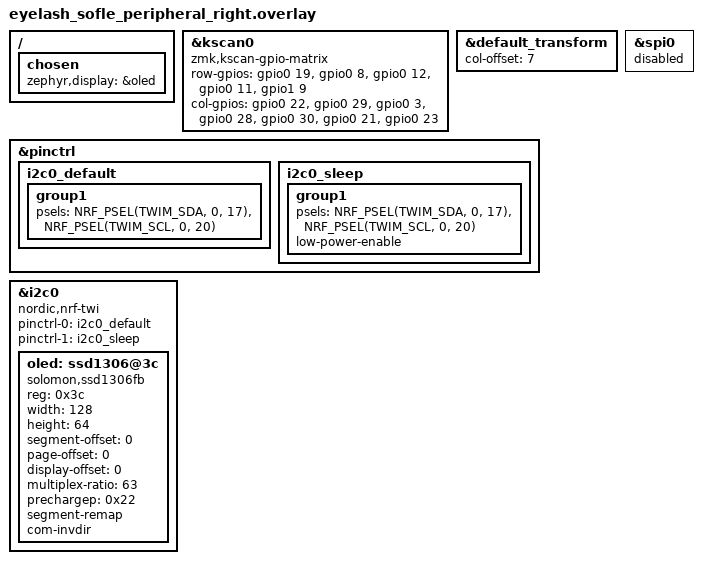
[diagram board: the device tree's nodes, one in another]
/*
*
* Copyright (c) 2021 Darryl deHaan
* SPDX-License-Identifier: MIT
*
*/
#include "eyelash_sofle.dtsi"

&kscan0 {
    compatible = "zmk,kscan-gpio-matrix";
    row-gpios
        = <&gpio0 19 (GPIO_ACTIVE_HIGH | GPIO_PULL_DOWN)>
        , <&gpio0 8 (GPIO_ACTIVE_HIGH | GPIO_PULL_DOWN)>
        , <&gpio0 12 (GPIO_ACTIVE_HIGH | GPIO_PULL_DOWN)>
        , <&gpio0 11 (GPIO_ACTIVE_HIGH | GPIO_PULL_DOWN)>
        , <&gpio1 9 (GPIO_ACTIVE_HIGH | GPIO_PULL_DOWN)>
        ;
    col-gpios
        = <&gpio0 22 GPIO_ACTIVE_HIGH>
        , <&gpio0 29 GPIO_ACTIVE_HIGH>
        , <&gpio0 3 GPIO_ACTIVE_HIGH>
        , <&gpio0 28 GPIO_ACTIVE_HIGH>
        , <&gpio0 30 GPIO_ACTIVE_HIGH>
        , <&gpio0 21 GPIO_ACTIVE_HIGH>
        , <&gpio0 23 GPIO_ACTIVE_HIGH>
        ;
};

&default_transform {
    col-offset = <7>;
};

/* SSD1306 OLED via I2C on P0.17 (SDA) and P0.20 (SCL).
 * spi0 uses the same pins, so it must be disabled. */
/ {
    chosen {
        zephyr,display = &oled;
    };
};

&pinctrl {
    i2c0_default: i2c0_default {
        group1 {
            psels = <NRF_PSEL(TWIM_SDA, 0, 17)>,
                    <NRF_PSEL(TWIM_SCL, 0, 20)>;
        };
    };
    i2c0_sleep: i2c0_sleep {
        group1 {
            psels = <NRF_PSEL(TWIM_SDA, 0, 17)>,
                    <NRF_PSEL(TWIM_SCL, 0, 20)>;
            low-power-enable;
        };
    };
};

&spi0 {
    status = "disabled";
};

&i2c0 {
    status = "okay";
    compatible = "nordic,nrf-twi";
    pinctrl-0 = <&i2c0_default>;
    pinctrl-1 = <&i2c0_sleep>;
    pinctrl-names = "default", "sleep";
    oled: ssd1306@3c {
        compatible = "solomon,ssd1306fb";
        reg = <0x3c>;
        width = <128>;
        height = <64>;
        segment-offset = <0>;
        page-offset = <0>;
        display-offset = <0>;
        multiplex-ratio = <63>;
        prechargep = <0x22>;
        segment-remap;
        com-invdir;
    };
};
